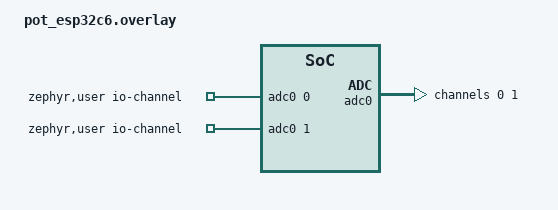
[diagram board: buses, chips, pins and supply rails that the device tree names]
/*
 * Real pressure input on the ESP32-C6-DevKitC, opt-in:
 *   west build ... -- -DEXTRA_DTC_OVERLAY_FILE=pot_esp32c6.overlay
 *
 * Pot wiper to GPIO1 (ADC1 channel 1), ends to 3V3 and GND. Channel 0 (GPIO0) is
 * the joystick input the C0116-DK has on board; tie GPIO0 to 3V3 here.
 */

#include <zephyr/dt-bindings/adc/adc.h>

/ {
	zephyr,user {
		io-channels = <&adc0 0>, <&adc0 1>;
	};
};

&adc0 {
	status = "okay";
	#address-cells = <1>;
	#size-cells = <0>;

	channel@0 {
		reg = <0>;
		zephyr,gain = "ADC_GAIN_1_4";
		zephyr,reference = "ADC_REF_INTERNAL";
		zephyr,acquisition-time = <ADC_ACQ_TIME_DEFAULT>;
		zephyr,resolution = <12>;
	};

	channel@1 {
		reg = <1>;
		zephyr,gain = "ADC_GAIN_1_4";
		zephyr,reference = "ADC_REF_INTERNAL";
		zephyr,acquisition-time = <ADC_ACQ_TIME_DEFAULT>;
		zephyr,resolution = <12>;
	};
};
